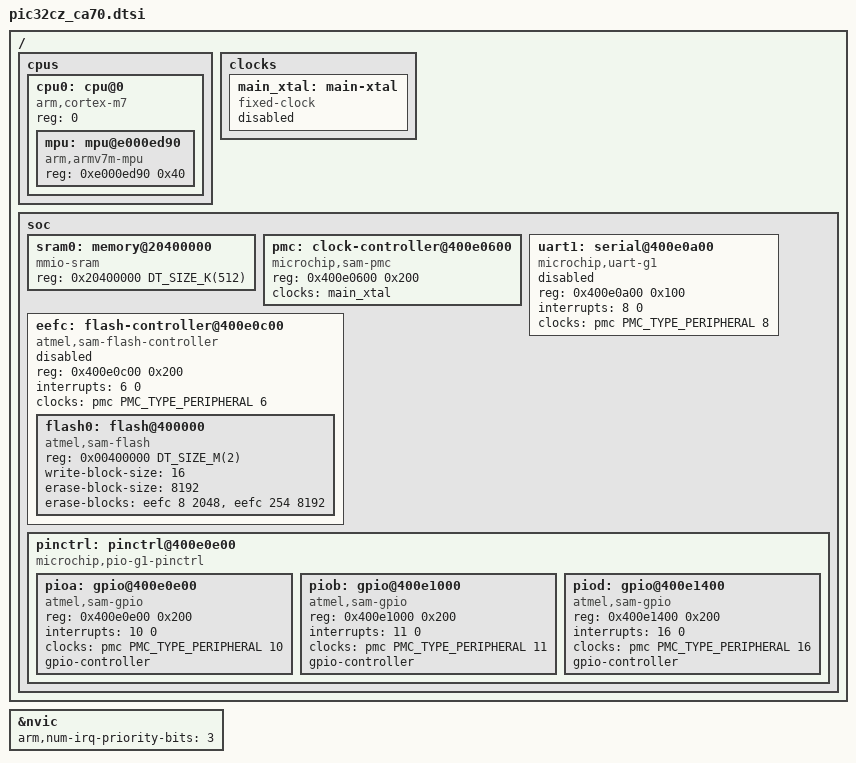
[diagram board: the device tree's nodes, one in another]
/*
 * SPDX-FileCopyrightText: Copyright The Zephyr Project Contributors
 *
 * SPDX-License-Identifier: Apache-2.0
 */

#include <arm/armv7-m.dtsi>
#include <mem.h>
#include <zephyr/dt-bindings/clock/microchip_sam_pmc.h>
#include <zephyr/dt-bindings/gpio/gpio.h>

/ {
	cpus {
		#address-cells = <1>;
		#size-cells = <0>;

		cpu0: cpu@0 {
			compatible = "arm,cortex-m7";
			reg = <0>;
			device_type = "cpu";
			#address-cells = <1>;
			#size-cells = <1>;

			mpu: mpu@e000ed90 {
				compatible = "arm,armv7m-mpu";
				reg = <0xe000ed90 0x40>;
			};
		};
	};

	clocks {
		main_xtal: main-xtal {
			compatible = "fixed-clock";
			#clock-cells = <0>;
			status = "disabled";
		};
	};

	soc {
		sram0: memory@20400000 {
			compatible = "mmio-sram";
			reg = <0x20400000 DT_SIZE_K(512)>;
		};

		pmc: clock-controller@400e0600 {
			compatible = "microchip,sam-pmc";
			reg = <0x400e0600 0x200>;
			#clock-cells = <2>;
			clocks = <&main_xtal>;
			clock-names = "main_xtal";
		};

		uart1: serial@400e0a00 {
			compatible = "microchip,uart-g1";
			reg = <0x400e0a00 0x100>;
			interrupts = <8 0>;
			clocks = <&pmc PMC_TYPE_PERIPHERAL 8>;
			status = "disabled";
		};

		eefc: flash-controller@400e0c00 {
			compatible = "atmel,sam-flash-controller";
			reg = <0x400e0c00 0x200>;
			ranges;
			interrupts = <6 0>;
			clocks = <&pmc PMC_TYPE_PERIPHERAL 6>;
			#address-cells = <1>;
			#size-cells = <1>;
			#erase-block-cells = <2>;
			status = "disabled";

			flash0: flash@400000 {
				compatible = "atmel,sam-flash", "soc-nv-flash";
				reg = <0x00400000 DT_SIZE_M(2)>;
				ranges = <0x0 0x00400000 DT_SIZE_M(2)>;
				write-block-size = <16>;
				erase-block-size = <8192>;
				erase-blocks = <&eefc 8 2048>, <&eefc 254 8192>;
				#address-cells = <1>;
				#size-cells = <1>;
			};
		};

		pinctrl: pinctrl@400e0e00 {
			compatible = "microchip,pio-g1-pinctrl";
			ranges = <0x400e0e00 0x400e0e00 0xa00>;
			#address-cells = <1>;
			#size-cells = <1>;

			pioa: gpio@400e0e00 {
				compatible = "atmel,sam-gpio";
				reg = <0x400e0e00 0x200>;
				interrupts = <10 0>;
				clocks = <&pmc PMC_TYPE_PERIPHERAL 10>;
				gpio-controller;
				#gpio-cells = <2>;
			};

			piob: gpio@400e1000 {
				compatible = "atmel,sam-gpio";
				reg = <0x400e1000 0x200>;
				interrupts = <11 0>;
				clocks = <&pmc PMC_TYPE_PERIPHERAL 11>;
				gpio-controller;
				#gpio-cells = <2>;
			};

			piod: gpio@400e1400 {
				compatible = "atmel,sam-gpio";
				reg = <0x400e1400 0x200>;
				interrupts = <16 0>;
				clocks = <&pmc PMC_TYPE_PERIPHERAL 16>;
				gpio-controller;
				#gpio-cells = <2>;
			};
		};
	};
};

&nvic {
	arm,num-irq-priority-bits = <3>;
};
